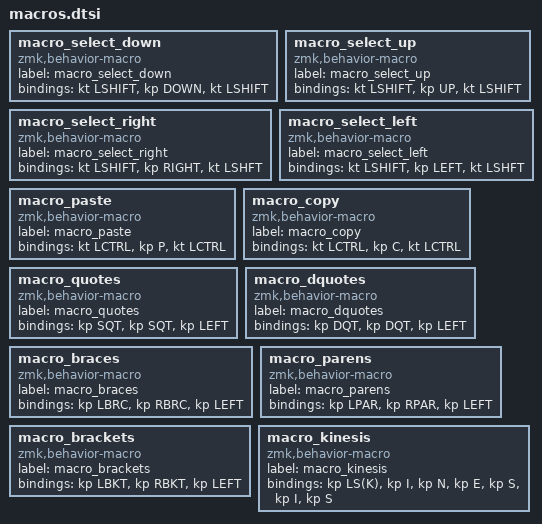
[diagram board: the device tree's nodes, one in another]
macro_select_down: macro_select_down{
compatible = "zmk,behavior-macro";
label = "macro_select_down";
#binding-cells = <0>;
bindings = <&kt LSHIFT>, <&kp DOWN>, <&kt LSHIFT>;
};
macro_select_up: macro_select_up{
compatible = "zmk,behavior-macro";
label = "macro_select_up";
#binding-cells = <0>;
bindings = <&kt LSHIFT>, <&kp UP>, <&kt LSHIFT>;
};
macro_select_right: macro_select_right{
compatible = "zmk,behavior-macro";
label = "macro_select_right";
#binding-cells = <0>;
bindings = <&kt LSHIFT>, <&kp RIGHT>, <&kt LSHFT>;
};
macro_select_left: macro_select_left{
compatible = "zmk,behavior-macro";
label = "macro_select_left";
#binding-cells = <0>;
bindings = <&kt LSHIFT>, <&kp LEFT>, <&kt LSHFT>;
};
macro_paste: macro_paste{
compatible = "zmk,behavior-macro";
label = "macro_paste";
#binding-cells = <0>;
bindings = <&kt LCTRL>, <&kp P>, <&kt LCTRL>;
};
macro_copy: macro_copy{
compatible = "zmk,behavior-macro";
label = "macro_copy";
#binding-cells = <0>;
bindings = <&kt LCTRL>, <&kp C>, <&kt LCTRL>;
};
macro_quotes: macro_quotes{
compatible = "zmk,behavior-macro";
label = "macro_quotes";
#binding-cells = <0>;
bindings = <&kp SQT>, <&kp SQT>, <&kp LEFT>;
};
macro_dquotes: macro_dquotes{
compatible = "zmk,behavior-macro";
label = "macro_dquotes";
#binding-cells = <0>;
bindings = <&kp DQT>, <&kp DQT>, <&kp LEFT>;
};
macro_braces: macro_braces{
compatible = "zmk,behavior-macro";
label = "macro_braces";
#binding-cells = <0>;
bindings = <&kp LBRC>, <&kp RBRC>, <&kp LEFT>;
};
macro_parens: macro_parens{
compatible = "zmk,behavior-macro";
label = "macro_parens";
#binding-cells = <0>;
bindings = <&kp LPAR>, <&kp RPAR>, <&kp LEFT>;
};
macro_brackets: macro_brackets{
compatible = "zmk,behavior-macro";
label = "macro_brackets";
#binding-cells = <0>;
bindings = <&kp LBKT>, <&kp RBKT>, <&kp LEFT>;
};
macro_kinesis: macro_kinesis{
compatible = "zmk,behavior-macro";
label = "macro_kinesis";
#binding-cells = <0>;
bindings = <&kp LS(K)>, <&kp I>, <&kp N>, <&kp E>, <&kp S>, <&kp I>, <&kp S>;
};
